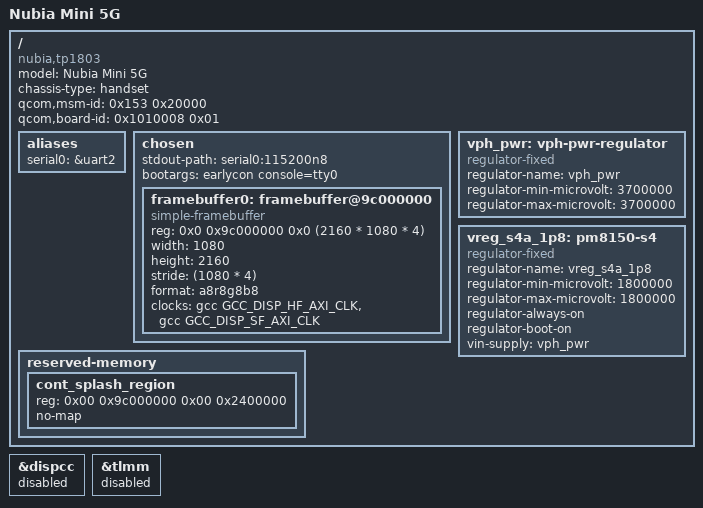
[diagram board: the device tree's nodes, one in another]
// SPDX-License-Identifier: BSD-3-Clause
/*
 * Copyright (c) 2017-2019, The Linux Foundation. All rights reserved.
 * Copyright (c) 2019, Linaro Limited
 */

/dts-v1/;

#include <dt-bindings/regulator/qcom,rpmh-regulator.h>
#include <dt-bindings/gpio/gpio.h>
#include "sm8150.dtsi"
#include "pm8150.dtsi"
#include "pm8150b.dtsi"
#include "pm8150l.dtsi"

/ {
	model = "Nubia Mini 5G";
	compatible = "nubia,tp1803", "qcom,sm8150";
	chassis-type = "handset";
	qcom,msm-id = <0x153 0x20000>;
	qcom,board-id = <0x1010008 0x01>;

	aliases {
		serial0 = &uart2;
	};

	chosen {
		#address-cells = <2>;
		#size-cells = <2>;
		ranges;

		stdout-path = "serial0:115200n8";
		bootargs = "earlycon console=tty0";

		framebuffer0: framebuffer@9c000000 {
			compatible = "simple-framebuffer";
			reg = <0x0 0x9c000000 0x0 (2160 * 1080 * 4)>;
			width = <1080>;
			height = <2160>;
			stride = <(1080 * 4)>;
			format = "a8r8g8b8";
			/*
			 * That's (going to be) a lot of clocks, but it's necessary due
			 * to unused clk cleanup & no panel driver yet (& no dispcc either)..
			 */
			clocks = <&gcc GCC_DISP_HF_AXI_CLK>,
				 <&gcc GCC_DISP_SF_AXI_CLK>;
		};
	};

	reserved-memory {
		/*
		/delete-node/ &xbl_mem;
		xbl_mem: memory@85e00000 {
			reg = <0x0 0x85e00000 0x0 0x140000>;
			no-map;
		};
		*/
		cont_splash_region {
			reg = <0x00 0x9c000000 0x00 0x2400000>;
			no-map;
		};
	};

	vph_pwr: vph-pwr-regulator {
		compatible = "regulator-fixed";
		regulator-name = "vph_pwr";
		regulator-min-microvolt = <3700000>;
		regulator-max-microvolt = <3700000>;
	};

	/*
	 * Apparently RPMh does not provide support for PM8150 S4 because it
	 * is always-on; model it as a fixed regulator.
	 */
	vreg_s4a_1p8: pm8150-s4 {
		compatible = "regulator-fixed";
		regulator-name = "vreg_s4a_1p8";

		regulator-min-microvolt = <1800000>;
		regulator-max-microvolt = <1800000>;

		regulator-always-on;
		regulator-boot-on;

		vin-supply = <&vph_pwr>;
	};
};

/*
&gmu {
	status = "okay";
};

&gpu {
	status = "okay";
};
*/
/*
&pon {
	mode-bootloader = <0x2>;
	mode-recovery = <0x1>;
};

&pon_pwrkey {
	status = "okay";
};

&pon_resin {
	status = "okay";

	linux,code = <KEY_VOLUMEDOWN>;
};
*/
/*
&qupv3_id_1 {
	status = "okay";
};
*/
/*
&remoteproc_adsp {
	status = "okay";
	firmware-name = "qcom/sm8150/adsp.mdt";
};

&remoteproc_cdsp {
	status = "okay";
	firmware-name = "qcom/sm8150/cdsp.mdt";
};

&remoteproc_mpss {
	status = "okay";
	firmware-name = "qcom/sm8150/modem.mdt";
};

&remoteproc_slpi {
	status = "okay";
	firmware-name = "qcom/sm8150/slpi.mdt";
};
*/
/*
&tlmm {
	gpio-reserved-ranges = <0 4>, <126 4>;
};

&uart2 {
	status = "okay";
};

&ufs_mem_hc {
	status = "okay";

	reset-gpios = <&tlmm 175 GPIO_ACTIVE_LOW>;

	vcc-supply = <&vreg_l10a_2p5>;
	vcc-max-microamp = <750000>;
	vccq-supply = <&vreg_l9a_1p2>;
	vccq-max-microamp = <700000>;
	vccq2-supply = <&vreg_s4a_1p8>;
	vccq2-max-microamp = <750000>;
};

&ufs_mem_phy {
	status = "okay";

	vdda-phy-supply = <&vdda_ufs_2ln_core_1>;
	vdda-pll-supply = <&vreg_l3c_1p2>;
};
*/
/*
&usb_1_hsphy {
	status = "okay";
	vdda-pll-supply = <&vdd_usb_hs_core>;
	vdda33-supply = <&vdda_usb_hs_3p1>;
	vdda18-supply = <&vdda_usb_hs_1p8>;
};

&usb_1_qmpphy {
	status = "okay";
	vdda-phy-supply = <&vreg_l3c_1p2>;
	vdda-pll-supply = <&vdda_usb_ss_dp_core_1>;
};

&usb_1 {
	status = "okay";
};

&usb_1_dwc3 {
	dr_mode = "peripheral";
};
*/
/*
&wifi {
	status = "okay";

	vdd-0.8-cx-mx-supply = <&vdda_wcss_pll>;
	vdd-1.8-xo-supply = <&vreg_l7a_1p8>;
	vdd-1.3-rfa-supply = <&vdda_wcss_adcdac_1>;
	vdd-3.3-ch0-supply = <&vreg_l11c_3p3>;
};
*/
&dispcc {
	status = "disabled";
};

&tlmm {
	status = "disabled";
};
